# PIC18LF8680 register map
Vendor: Microchip
Architecture 18xxxx. Special function registers and configuration words.
Registers are 8-bit, read-write, no defined reset value unless marked. A register's access mark holds for its fields unless they carry their own. Addresses are absolute, and some are shared; only a register's first bit layout is shown; lines under a group give offsets from that group; [hi:lo] are bit positions; {n}, {i} and the like mark numbered series; 'fields as' and 'values as' point back to an identical list; <NAME> marks a mode.

## Further device data
pins=1: RH2/A18; 2: RH3/A19; 3: RE1/WR/AD9; 4: RE0/RD/AD8; 5: RG0/CANTX1; 6: RG1/CANTX2; 7: RG2/CANRX; 8: RG3; 9: RG5/MCLR/Vpp; 10: RG5; 11: RG4/P1D; 12: Vss; 13: Vdd; 14: RF7/SS; 15: RF6/AN11/C1IN-; 16: RF5/AN10/C1IN+/CVref; 17: RF4/AN9/C2IN-; 18: RF3/AN8/C2IN+; 19: RF2/AN7/C1OUT; 20: RH7/AN15/P1B; 21: RH6/AN14/P1C; 22: RH5/AN13; 23: RH4/AN12; 24: RF1/AN6/C2OUT; 25: RF0/AN5; 26: AVdd; 27: AVss; 28: RA3/AN3/Vref+; 29: RA2/AN2/Vref-; 30: RA1/AN1; 31: RA0/AN0; 32: Vss; 33: Vdd; 34: RA5/AN4/LVDIN; 35: RA4/T0CKI; 36: RC1/T1OSI/CCP2; 37: RC0/T1OSO/T13CKI; 38: RC6/TX/CK; 39: RC7/RX/DT; 40: RJ4/BA0; 41: RJ5/CE; 42: RJ7/UB; 43: RJ6/LB; 44: RC2/CCP1/P1A; 45: RC3/SCK/SCL; 46: RC4/SDI/SDA; 47: RC5/SDO; 48: RB7/KBI3/PGD; 49: Vdd; 50: OSC1/CLKI; 51: OSC2/CLKO/RA6; 52: Vss; 53: RB6/KBI2/PGC; 54: RB5/KBI1/PGM; 55: RB4/KBI0; 56: RB3/INT3/CCP2; 57: RB2/INT2; 58: RB1/INT1; 59: RB0/INT0; 60: RJ3/WRH; 61: RJ2/WRL; 62: RJ1/OE; 63: RJ0/ALE; 64: RD7/PSP7/AD7; 65: RD6/PSP6/AD6; 66: RD5/PSP5/AD5; 67: RD4/PSP4/AD4; 68: RD3/PSP3/AD3; 69: RD2/PSP2/AD2; 70: RD1/PSP1/AD1; 71: Vss; 72: Vdd; 73: RD0/PSP0/AD0; 74: RE7/CCP2/AD15; 75: RE6/AD14/P1B; 76: RE5/AD13/P1C; 77: RE4/AD12; 78: RE3/AD11; 79: RE2/CS/AD10; 80: RH0/A16; 81: RH1/A17

## CONFIG — Configuration words, addresses in ProgramSpace
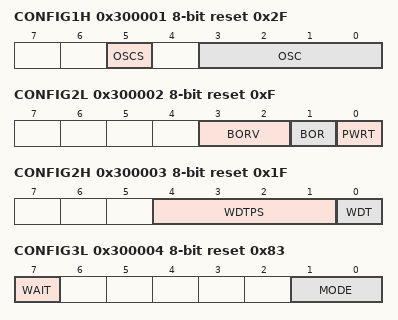
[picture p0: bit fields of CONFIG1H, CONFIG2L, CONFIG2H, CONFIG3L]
0x300001 CONFIG1H reset 0x2F
  [5] OSCS — Osc. Switch Enable
    0=ON (Timer1 oscillator system clock switch option is enabled (oscillator switching is enabled)); 1=OFF (Oscillator system clock switch option is disabled (main oscillator is source))
  [3:0] OSC — Oscillator
    15=RC-OSC2 as RA6; 14=HSSWPLL (HS oscillator with SW enabled 4x PLL); 13=ECIOSWPLL (EC oscillator with OSC2 configured as RA6 and SW enabled 4x PLL); 12=ECIOPLL (EC oscillator with OSC2 configured as RA6 and HW enabled 4x PLL); 7=RCIO (RC oscillator with OSC2 configured as RA6); 6=HSPLL (HS oscillator with HW enabled 4x PLL); 5=ECIO (EC oscillator with OSC2 configured as RA6); 4=EC (EC oscillator with OSC2 configured as divide by 4 clock output); 3=RC (RC oscillator with OSC2 configured as divide by 4 clock output); 2=HS (HS oscillator); 1=XT (XT oscillator); 0=LP (LP oscillator)
0x300002 CONFIG2L reset 0xF
  [3:2] BORV — Brown Out Voltage
    3=VBOR set to 2.0V; 2=VBOR set to 2.7V; 1=VBOR set to 4.2V; 0=VBOR set to 4.5V
  [1] BOR — Brown Out Detect
    1=ON (Brown-out Reset enabled); 0=OFF (Brown-out Reset disabled)
  [0] PWRT — Power Up Timer
    1=OFF (PWRT disabled); 0=ON (PWRT enabled)
0x300003 CONFIG2H reset 0x1F
  [4:1] WDTPS — Watchdog Postscaler
    15=1:32768; 14=1:16384; 13=1:8192; 12=1:4096; 11=1:2048; 10=1:1024; 9=1:512; 8=1:256; 7=1:128; 6=1:64; 5=1:32; 4=1:16; 3=1:8; 2=1:4; 1=1:2; 0=1:1
  [0] WDT — Watchdog Timer
    1=ON (WDT enabled); 0=OFF (WDT disabled (control is placed on the SWDTEN bit))
0x300004 CONFIG3L reset 0x83
  [7] WAIT — External Bus Wait
    1=OFF (Wait selections unavailable for table reads and table writes); 0=ON (Wait selections for table reads and table writes are determined by WAIT1:WAIT0 bits (MEMCOM<5:4>))
  [1:0] MODE — Processor Mode
    3=MC (Microcontroller mode); 2=MP (Microprocessor mode); 1=MPB (Microprocessor with Boot Block mode); 0=EM (Extended Microcontroller mode)
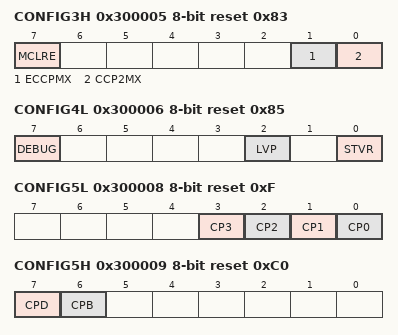
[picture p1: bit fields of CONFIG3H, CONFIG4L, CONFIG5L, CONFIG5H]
0x300005 CONFIG3H reset 0x83
  [7] MCLRE — MCLR enable
    1=ON (MCLR pin enabled, RG5 input pin disabled); 0=OFF (RG5 input enabled, MCLR disabled)
  [1] ECCPMX — ECCP Mux
    1=PORTE (P1B, P1C are multiplexed with RE6, RE5); 0=PORTH (P1B, P1C are multiplexed with RH7, RH6)
  [0] CCP2MX — CCP2 Mux
    1=ON (CCP2 input/output is multiplexed with RC1); 0=OFF (CCP2 is multiplexed with RB3 in Extended Microcontroller, Microprocessor or Microprocessor with Boot Block mode. Or with RE7 in Microcontroller mode.)
0x300006 CONFIG4L reset 0x85
  [7] DEBUG — Background Debugger Enable bit
    1=OFF (Background debugger disabled. RB6 and RB7 configured as general purpose I/O pins.); 0=ON (Background debugger enabled. RB6 and RB7 are dedicated to in-circuit debug.)
  [2] LVP — Low Voltage Program
    1=ON (Low-voltage ICSP enabled); 0=OFF (Low-voltage ICSP disabled)
  [0] STVR — Stack Overflow Reset
    1=ON (Stack full/underflow will cause Reset); 0=OFF (Stack full/underflow will not cause Reset)
0x300008 CONFIG5L reset 0xF
  [3] CP3 — Code Protect 00C000-00FFFF
    1=OFF (Block 3 (00C000-00FFFFh) not code-protected); 0=ON (Block 3 (00C000-00FFFFh) code-protected)
  [2] CP2 — Code Protect 008000-00BFFF
    1=OFF (Block 2 (008000-00BFFFh) not code-protected); 0=ON (Block 2 (008000-00BFFFh) code-protected)
  [1] CP1 — Code Protect 0004000-007FFF
    1=OFF (Block 1 (004000-007FFFh) not code-protected); 0=ON (Block 1 (004000-007FFFh) code-protected)
  [0] CP0 — Code Protect 000800-0003FFF
    1=OFF (Block 0 (000800-003FFFh) not code-protected); 0=ON (Block 0 (000800-003FFFh) code-protected)
0x300009 CONFIG5H reset 0xC0
  [7] CPD — Data EE Read Protect
    1=OFF (Data EEPROM not code-protected); 0=ON (Data EEPROM code-protected)
  [6] CPB — Code Protect Boot
    1=OFF (Boot block (000000-0007FFh) not code-protected); 0=ON (Boot block (000000-0007FFh) code-protected)
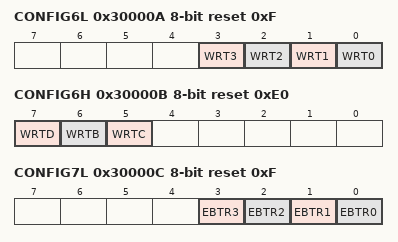
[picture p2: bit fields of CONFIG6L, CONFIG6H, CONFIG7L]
0x30000A CONFIG6L reset 0xF
  [3] WRT3 — Table Write Protect 0C000-0FFFF
    1=OFF (Block 3 (00C000-00FFFFh) not write-protected); 0=ON (Block 3 (00C000-00FFFFh) write-protected)
  [2] WRT2 — Table Write Protect 08000-0BFFF
    1=OFF (Block 2 (008000-00BFFFh) not write-protected); 0=ON (Block 2 (008000-00BFFFh) write-protected)
  [1] WRT1 — Table Write Protect 004000-007FFF
    1=OFF (Block 1 (004000-007FFFh) not write-protected); 0=ON (Block 1 (004000-007FFFh) write-protected)
  [0] WRT0 — Table Write Protect 00800-003FFF
    1=OFF (Block 0 (000800-003FFFh) not write-protected); 0=ON (Block 0 (000800-003FFFh) write-protected)
0x30000B CONFIG6H reset 0xE0
  [7] WRTD — Data EE Write Protect
    1=OFF (Data EEPROM not write-protected); 0=ON (Data EEPROM write-protected)
  [6] WRTB — Table Write Protect Boot
    1=OFF (Boot block (000000-0007FFh) not write-protected); 0=ON (Boot block (000000-0007FFh) write-protected)
  [5] WRTC — Config. Write Protect
    1=OFF (Configuration registers (300000-3000FFh) not write-protected); 0=ON (Configuration registers (300000-3000FFh) write-protected)
0x30000C CONFIG7L reset 0xF
  [3] EBTR3 — Table Read Protect 0C000-0FFFF
    1=OFF (Block 3 (00C000-00FFFFh) not protected from table reads executed in other blocks); 0=ON (Block 3 (00C000-00FFFFh) protected from table reads executed in other blocks)
  [2] EBTR2 — Table Read Protect 08000-0BFFF
    1=OFF (Block 2 (008000-00BFFFh) not protected from table reads executed in other blocks); 0=ON (Block 2 (008000-00BFFFh) protected from table reads executed in other blocks)
  [1] EBTR1 — Table Read Protect 004000-07FFF
    1=OFF (Block 1 (004000-007FFFh) not protected from table reads executed in other blocks); 0=ON (Block 1 (004000-007FFFh) protected from table reads executed in other blocks)
  [0] EBTR0 — Table Read Protect 00800-003FFF
    1=OFF (Block 0 (000800-003FFFh) not protected from table reads executed in other blocks); 0=ON (Block 0 (000800-003FFFh) protected from table reads executed in other blocks)
0x30000D CONFIG7H reset 0x40
  [6] EBTRB — Table Read Protect Boot
    1=OFF (Boot block (000000-0007FFh) not protected from table reads executed in other blocks); 0=ON (Boot block (000000-0007FFh) protected from table reads executed in other blocks)
